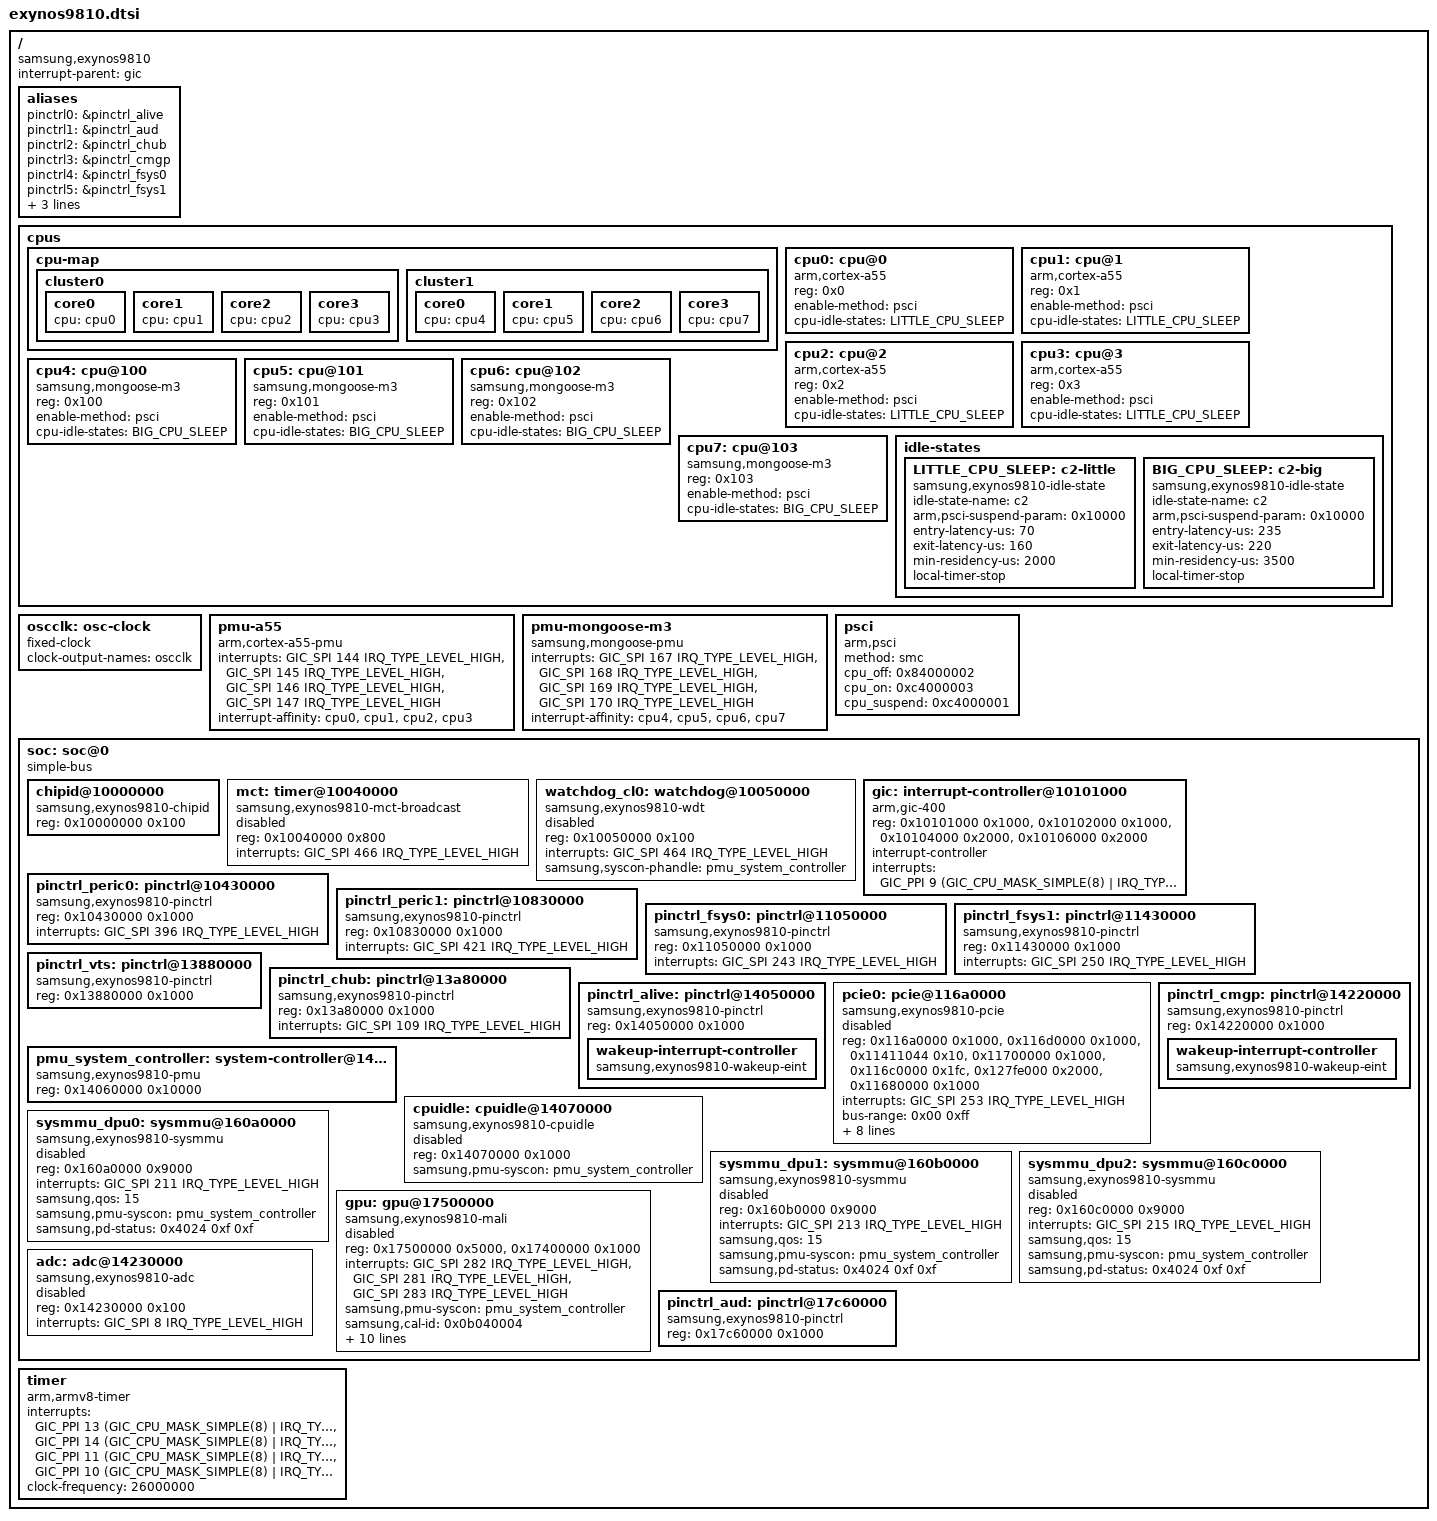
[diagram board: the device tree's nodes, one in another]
// SPDX-License-Identifier: GPL-2.0 OR BSD-3-Clause
/*
 * Samsung Exynos 9810 SoC device tree source
 *
 * Copyright (c) 2024 Markuss Broks <markuss.broks@gmail.com>
 * Copyright (c) 2024 Maksym Holovach <nergzd@nergzd723.xyz>
 */

#include <dt-bindings/interrupt-controller/arm-gic.h>

/ {
	compatible = "samsung,exynos9810";
	#address-cells = <2>;
	#size-cells = <1>;

	interrupt-parent = <&gic>;

	aliases {
		pinctrl0 = &pinctrl_alive;
		pinctrl1 = &pinctrl_aud;
		pinctrl2 = &pinctrl_chub;
		pinctrl3 = &pinctrl_cmgp;
		pinctrl4 = &pinctrl_fsys0;
		pinctrl5 = &pinctrl_fsys1;
		pinctrl6 = &pinctrl_peric0;
		pinctrl7 = &pinctrl_peric1;
		pinctrl8 = &pinctrl_vts;
	};

	cpus {
		#address-cells = <1>;
		#size-cells = <0>;

		cpu-map {
			cluster0 {
				core0 {
					cpu = <&cpu0>;
				};
				core1 {
					cpu = <&cpu1>;
				};
				core2 {
					cpu = <&cpu2>;
				};
				core3 {
					cpu = <&cpu3>;
				};
			};

			cluster1 {
				core0 {
					cpu = <&cpu4>;
				};
				core1 {
					cpu = <&cpu5>;
				};
				core2 {
					cpu = <&cpu6>;
				};
				core3 {
					cpu = <&cpu7>;
				};
			};
		};

		cpu0: cpu@0 {
			device_type = "cpu";
			compatible = "arm,cortex-a55";
			reg = <0x0>;
			enable-method = "psci";
			cpu-idle-states = <&LITTLE_CPU_SLEEP>;
		};

		cpu1: cpu@1 {
			device_type = "cpu";
			compatible = "arm,cortex-a55";
			reg = <0x1>;
			enable-method = "psci";
			cpu-idle-states = <&LITTLE_CPU_SLEEP>;
		};

		cpu2: cpu@2 {
			device_type = "cpu";
			compatible = "arm,cortex-a55";
			reg = <0x2>;
			enable-method = "psci";
			cpu-idle-states = <&LITTLE_CPU_SLEEP>;
		};

		cpu3: cpu@3 {
			device_type = "cpu";
			compatible = "arm,cortex-a55";
			reg = <0x3>;
			enable-method = "psci";
			cpu-idle-states = <&LITTLE_CPU_SLEEP>;
		};

		cpu4: cpu@100 {
			device_type = "cpu";
			compatible = "samsung,mongoose-m3";
			reg = <0x100>;
			enable-method = "psci";
			cpu-idle-states = <&BIG_CPU_SLEEP>;
		};

		cpu5: cpu@101 {
			device_type = "cpu";
			compatible = "samsung,mongoose-m3";
			reg = <0x101>;
			enable-method = "psci";
			cpu-idle-states = <&BIG_CPU_SLEEP>;
		};

		cpu6: cpu@102 {
			device_type = "cpu";
			compatible = "samsung,mongoose-m3";
			reg = <0x102>;
			enable-method = "psci";
			cpu-idle-states = <&BIG_CPU_SLEEP>;
		};

		cpu7: cpu@103 {
			device_type = "cpu";
			compatible = "samsung,mongoose-m3";
			reg = <0x103>;
			enable-method = "psci";
			cpu-idle-states = <&BIG_CPU_SLEEP>;
		};

		/*
		 * Core power-down (C2) values from the crownlte 4.9 DT
		 * (bootcl-cpu-sleep / nobootcl-cpu-sleep). Deliberately not
		 * "arm,idle-state": entering C2 needs the FlexPMU steps of
		 * drivers/cpuidle/cpuidle-exynos9810.c, which the generic
		 * PSCI idle driver does not perform. The arch timer stops
		 * when the core is powered down (4.9 ticked on the MCT local
		 * timers), so these states need the MCT tick broadcast.
		 * Cluster power-down (4.9 CPD) is not described.
		 */
		idle-states {
			LITTLE_CPU_SLEEP: c2-little {
				compatible = "samsung,exynos9810-idle-state";
				idle-state-name = "c2";
				arm,psci-suspend-param = <0x10000>;
				entry-latency-us = <70>;
				exit-latency-us = <160>;
				min-residency-us = <2000>;
				local-timer-stop;
			};

			BIG_CPU_SLEEP: c2-big {
				compatible = "samsung,exynos9810-idle-state";
				idle-state-name = "c2";
				arm,psci-suspend-param = <0x10000>;
				entry-latency-us = <235>;
				exit-latency-us = <220>;
				min-residency-us = <3500>;
				local-timer-stop;
			};
		};
	};

	oscclk: osc-clock {
		compatible = "fixed-clock";
		#clock-cells = <0>;
		clock-output-names = "oscclk";
	};

	pmu-a55 {
		compatible = "arm,cortex-a55-pmu";
		interrupts = <GIC_SPI 144 IRQ_TYPE_LEVEL_HIGH>,
			     <GIC_SPI 145 IRQ_TYPE_LEVEL_HIGH>,
			     <GIC_SPI 146 IRQ_TYPE_LEVEL_HIGH>,
			     <GIC_SPI 147 IRQ_TYPE_LEVEL_HIGH>;
		interrupt-affinity = <&cpu0>,
				     <&cpu1>,
				     <&cpu2>,
				     <&cpu3>;
	};

	pmu-mongoose-m3 {
		compatible = "samsung,mongoose-pmu";
		interrupts = <GIC_SPI 167 IRQ_TYPE_LEVEL_HIGH>,
			     <GIC_SPI 168 IRQ_TYPE_LEVEL_HIGH>,
			     <GIC_SPI 169 IRQ_TYPE_LEVEL_HIGH>,
			     <GIC_SPI 170 IRQ_TYPE_LEVEL_HIGH>;
		interrupt-affinity = <&cpu4>,
				     <&cpu5>,
				     <&cpu6>,
				     <&cpu7>;
	};

	psci {
		compatible = "arm,psci";
		method = "smc";
		cpu_off = <0x84000002>;
		cpu_on = <0xc4000003>;
		cpu_suspend = <0xc4000001>;
	};

	soc: soc@0 {
		compatible = "simple-bus";
		ranges = <0x0 0x0 0x0 0x20000000>;

		#address-cells = <1>;
		#size-cells = <1>;

		chipid@10000000 {
			compatible = "samsung,exynos9810-chipid",
				     "samsung,exynos850-chipid";
			reg = <0x10000000 0x100>;
		};

		/*
		 * Multi Core Timer. Only global comparator 0 (MCT G0) is
		 * described, for the tick broadcast driver exynos9810-mct-bc.
		 * 4.9 used SPIs 466-469 (G0-G3) and 470-477 (L0-L7).
		 * Deliberately not "samsung,exynos4210-mct": that early
		 * TIMER_OF driver panics on any clock or write failure.
		 */
		mct: timer@10040000 {
			compatible = "samsung,exynos9810-mct-broadcast";
			reg = <0x10040000 0x800>;
			interrupts = <GIC_SPI 466 IRQ_TYPE_LEVEL_HIGH>;
			status = "disabled";
		};

		watchdog_cl0: watchdog@10050000 {
			compatible = "samsung,exynos9810-wdt";
			reg = <0x10050000 0x100>;
			interrupts = <GIC_SPI 464 IRQ_TYPE_LEVEL_HIGH>;
			samsung,syscon-phandle = <&pmu_system_controller>;
			status = "disabled";
		};

		gic: interrupt-controller@10101000 {
			compatible = "arm,gic-400";
			reg = <0x10101000 0x1000>,
			      <0x10102000 0x1000>,
			      <0x10104000 0x2000>,
			      <0x10106000 0x2000>;
			#interrupt-cells = <3>;
			interrupt-controller;
			interrupts = <GIC_PPI 9 (GIC_CPU_MASK_SIMPLE(8) |
						 IRQ_TYPE_LEVEL_HIGH)>;
			#address-cells = <0>;
			#size-cells = <1>;
		};

		pinctrl_peric0: pinctrl@10430000 {
			compatible = "samsung,exynos9810-pinctrl";
			reg = <0x10430000 0x1000>;
			interrupts = <GIC_SPI 396 IRQ_TYPE_LEVEL_HIGH>;
		};

		pinctrl_peric1: pinctrl@10830000 {
			compatible = "samsung,exynos9810-pinctrl";
			reg = <0x10830000 0x1000>;
			interrupts = <GIC_SPI 421 IRQ_TYPE_LEVEL_HIGH>;
		};

		pinctrl_fsys0: pinctrl@11050000 {
			compatible = "samsung,exynos9810-pinctrl";
			reg = <0x11050000 0x1000>;
			interrupts = <GIC_SPI 243 IRQ_TYPE_LEVEL_HIGH>;
		};

		pinctrl_fsys1: pinctrl@11430000 {
			compatible = "samsung,exynos9810-pinctrl";
			reg = <0x11430000 0x1000>;
			interrupts = <GIC_SPI 250 IRQ_TYPE_LEVEL_HIGH>;
		};

		pinctrl_vts: pinctrl@13880000 {
			compatible = "samsung,exynos9810-pinctrl";
			reg = <0x13880000 0x1000>;
		};

		pinctrl_chub: pinctrl@13a80000 {
			compatible = "samsung,exynos9810-pinctrl";
			reg = <0x13a80000 0x1000>;
			interrupts = <GIC_SPI 109 IRQ_TYPE_LEVEL_HIGH>;
		};

		pinctrl_alive: pinctrl@14050000 {
			compatible = "samsung,exynos9810-pinctrl";
			reg = <0x14050000 0x1000>;

			wakeup-interrupt-controller {
				compatible = "samsung,exynos9810-wakeup-eint",
					     "samsung,exynos850-wakeup-eint",
					     "samsung,exynos7-wakeup-eint";
			};
		};

		/*
		 * PCIe RC channel 0 (BCM4361 Wi-Fi), 4.9 pcie0@116A0000. Same
		 * register windows as 4.9 ("sysreg" is the 16-byte PHY/PCS lane
		 * control window in SYSREG_FSYS1), ip-ver 0x981000, Gen2 x1,
		 * INTx only (4.9 use-msi = "false"). No dma-coherent and no
		 * SysMMU: see Documentation/crownlte/wifi-port.md.
		 */
		pcie0: pcie@116a0000 {
			compatible = "samsung,exynos9810-pcie";
			reg = <0x116a0000 0x1000>,
			      <0x116d0000 0x1000>,
			      <0x11411044 0x10>,
			      <0x11700000 0x1000>,
			      <0x116c0000 0x1fc>,
			      <0x127fe000 0x2000>,
			      <0x11680000 0x1000>;
			reg-names = "elbi", "phy", "sysreg", "dbi", "pcs", "config", "ia";
			interrupts = <GIC_SPI 253 IRQ_TYPE_LEVEL_HIGH>;
			#address-cells = <3>;
			#size-cells = <2>;
			device_type = "pci";
			ranges = <0x82000000 0x0 0x11800000 0x11800000 0x0 0xff0000>;
			bus-range = <0x00 0xff>;
			#interrupt-cells = <1>;
			interrupt-map-mask = <0 0 0 0>;
			interrupt-map = <0 0 0 0 &gic GIC_SPI 253 IRQ_TYPE_LEVEL_HIGH>;
			num-lanes = <1>;
			max-link-speed = <2>;
			samsung,channel = <0>;
			samsung,use-ia;
			samsung,pmu-syscon = <&pmu_system_controller>;
			status = "disabled";
		};

		pmu_system_controller: system-controller@14060000 {
			compatible = "samsung,exynos9810-pmu",
				     "samsung,exynos7-pmu", "syscon";
			reg = <0x14060000 0x10000>;
		};

		/*
		 * reg is the FlexPMU interrupt generator (PMU_INTR_GEN). The
		 * driver only reads it for diagnostics; the C2 sequences are
		 * the PMUCAL ones, already mapped by CAL.
		 */
		cpuidle: cpuidle@14070000 {
			compatible = "samsung,exynos9810-cpuidle";
			reg = <0x14070000 0x1000>;
			samsung,pmu-syscon = <&pmu_system_controller>;
			status = "disabled";
		};

		pinctrl_cmgp: pinctrl@14220000 {
			compatible = "samsung,exynos9810-pinctrl";
			reg = <0x14220000 0x1000>;

			wakeup-interrupt-controller {
				compatible = "samsung,exynos9810-wakeup-eint",
					     "samsung,exynos850-wakeup-eint",
					     "samsung,exynos7-wakeup-eint";
			};
		};

		/*
		 * DPU System MMUs (4.9 sysmmu_dpu0..2), SysMMU v7.x with the
		 * non-VM register layout (PT_BASE 0x0c, flush 0x10-0x24, fault
		 * 0x70/0x78, CAPA0/1 0x870/0x874). "samsung,exynos9810-sysmmu"
		 * selects the 4.9 programming model in exynos-iommu: CFG =
		 * (reset value & ~0x301f1f8c) | QoS override | samsung,qos, no
		 * access-protection check (CFG_EAP) and no PTE protection bits,
		 * range TLB flushes, faults never panic. Ports: dpu0 VGRF/VGF,
		 * dpu1 G0/VG0, dpu2 G1/VG1/WB. Interrupt 0 is the non-secure
		 * fault IRQ (4.9 index 1 = secure, not used here). The secure
		 * SFR blocks (0x160d0000, 0x160e0000, 0x160f0000) must not be
		 * touched from the kernel. No clocks: the GATE_SYSMMU_DPUDn
		 * vclks are HWACG Q-channel gates whose enable/disable are
		 * no-ops. samsung,pd-status: PMU DPU_STATUS must read 0xf
		 * before any SFR access.
		 * Disabled here; enabled with iommus on decon_f by
		 * exynos9810-crownlte-delayed-ufs-display-s2-iommu-diag.dts.
		 * See Documentation/crownlte/display-iommu.md.
		 */
		sysmmu_dpu0: sysmmu@160a0000 {
			compatible = "samsung,exynos9810-sysmmu", "samsung,exynos-sysmmu";
			reg = <0x160a0000 0x9000>;
			interrupts = <GIC_SPI 211 IRQ_TYPE_LEVEL_HIGH>;
			samsung,qos = <15>;
			samsung,pmu-syscon = <&pmu_system_controller>;
			samsung,pd-status = <0x4024 0xf 0xf>;
			#iommu-cells = <0>;
			status = "disabled";
		};

		sysmmu_dpu1: sysmmu@160b0000 {
			compatible = "samsung,exynos9810-sysmmu", "samsung,exynos-sysmmu";
			reg = <0x160b0000 0x9000>;
			interrupts = <GIC_SPI 213 IRQ_TYPE_LEVEL_HIGH>;
			samsung,qos = <15>;
			samsung,pmu-syscon = <&pmu_system_controller>;
			samsung,pd-status = <0x4024 0xf 0xf>;
			#iommu-cells = <0>;
			status = "disabled";
		};

		sysmmu_dpu2: sysmmu@160c0000 {
			compatible = "samsung,exynos9810-sysmmu", "samsung,exynos-sysmmu";
			reg = <0x160c0000 0x9000>;
			interrupts = <GIC_SPI 215 IRQ_TYPE_LEVEL_HIGH>;
			samsung,qos = <15>;
			samsung,pmu-syscon = <&pmu_system_controller>;
			samsung,pd-status = <0x4024 0xf 0xf>;
			#iommu-cells = <0>;
			status = "disabled";
		};

		/*
		 * Mali-G72 MP18 (Bifrost THEx), 4.9 crownlte mali@17500000. The
		 * second window is CMU_G3D, read only (embedded G3D user mux).
		 * Clock: ACPM vclk dvfs_g3d (CAL 0x0b040004, 4.9 g3d_cmu_cal_id);
		 * the firmware picks vdd_g3d (S2MPS18 BUCK6). Power domain: PMU
		 * embedded_g3d (cfg 0x14064040, status 0x14064044, CAL 0xb1380008)
		 * is never switched by this driver. samsung,dvfs-table rows are the
		 * 4.9 gpu_dvfs_table columns clock, min/max utilisation, down stay
		 * count and MIF floor (kHz); samsung,interactive-info is the 4.9
		 * interactive_info <highspeed clock, load, delay>.
		 */
		gpu: gpu@17500000 {
			compatible = "samsung,exynos9810-mali", "arm,mali-bifrost";
			reg = <0x17500000 0x5000>, <0x17400000 0x1000>;
			interrupts = <GIC_SPI 282 IRQ_TYPE_LEVEL_HIGH>,
				     <GIC_SPI 281 IRQ_TYPE_LEVEL_HIGH>,
				     <GIC_SPI 283 IRQ_TYPE_LEVEL_HIGH>;
			interrupt-names = "JOB", "MMU", "GPU";
			samsung,pmu-syscon = <&pmu_system_controller>;
			samsung,cal-id = <0x0b040004>;
			/*
			 * 4.9 pd-embedded_g3d@14064040 cal_id / need_smc. Used
			 * only with samsung,g3d-power-control (default off).
			 */
			samsung,g3d-pd-cal-id = <0xb1380008>;
			samsung,g3d-need-smc = <0x17410204>;
			samsung,dvfs-table = <572000 78 100 5 1794000>,
					     <546000 78  99 1 1794000>,
					     <455000 78  85 1 1539000>,
					     <338000 78  85 1 1352000>,
					     <299000 78  85 1 1014000>,
					     <260000 78  85 1  421000>;
			samsung,interactive-info = <338000 94 0>;
			samsung,dvfs-period-ms = <30>;
			#cooling-cells = <2>;
			status = "disabled";
		};

		/*
		 * CMGP ADC, 12 channels, 12 bit (4.9 adc@14230000,
		 * "samsung,exynos-adc-v3", SPI 8). The gate clock
		 * (GATE_ADC_CMGP) comes from the board clock provider.
		 */
		adc: adc@14230000 {
			compatible = "samsung,exynos9810-adc";
			reg = <0x14230000 0x100>;
			interrupts = <GIC_SPI 8 IRQ_TYPE_LEVEL_HIGH>;
			#io-channel-cells = <1>;
			status = "disabled";
		};

		pinctrl_aud: pinctrl@17c60000 {
			compatible = "samsung,exynos9810-pinctrl";
			reg = <0x17c60000 0x1000>;
		};
	};

	timer {
		compatible = "arm,armv8-timer";
		/* Hypervisor Virtual Timer interrupt is not wired to GIC */
		interrupts = <GIC_PPI 13 (GIC_CPU_MASK_SIMPLE(8) | IRQ_TYPE_LEVEL_LOW)>,
			     <GIC_PPI 14 (GIC_CPU_MASK_SIMPLE(8) | IRQ_TYPE_LEVEL_LOW)>,
			     <GIC_PPI 11 (GIC_CPU_MASK_SIMPLE(8) | IRQ_TYPE_LEVEL_LOW)>,
			     <GIC_PPI 10 (GIC_CPU_MASK_SIMPLE(8) | IRQ_TYPE_LEVEL_LOW)>;
		/*
		 * Non-updatable, broken stock Samsung bootloader does not
		 * configure CNTFRQ_EL0
		 */
		clock-frequency = <26000000>;
	};
};

#include "exynos9810-pinctrl.dtsi"
#include "arm/samsung/exynos-syscon-restart.dtsi"
